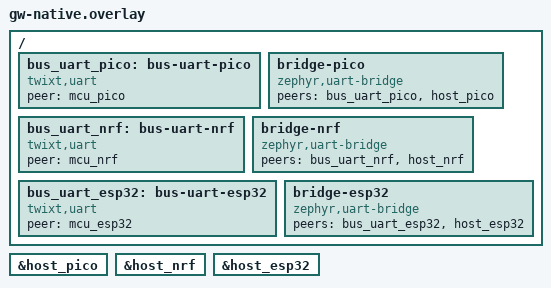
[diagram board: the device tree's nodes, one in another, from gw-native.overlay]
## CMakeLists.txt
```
# SPDX-License-Identifier: Apache-2.0
cmake_minimum_required(VERSION 3.20.0)

# CONF_FILE selects the hardware role; MCU selects a simulated bus participant.
set(role bd)
if(CONF_FILE MATCHES "gw.conf" OR MCU STREQUAL "gw")
  set(role gw)
endif()
set(CONF_FILE ${role}.conf)
list(PREPEND EXTRA_CONF_FILE ${CMAKE_CURRENT_SOURCE_DIR}/prj.conf)
set(role_overlay ${role}.overlay)

# Include the same board settings with either role, also under sysbuild.
set(board_target "${BOARD}")
if(BOARD_QUALIFIERS AND NOT BOARD MATCHES "/")
  string(APPEND board_target "/${BOARD_QUALIFIERS}")
endif()
string(REPLACE "/" "_" board_config "${board_target}")
if(EXISTS "${CMAKE_CURRENT_SOURCE_DIR}/boards/${board_config}.conf")
  list(APPEND EXTRA_CONF_FILE ${CMAKE_CURRENT_SOURCE_DIR}/boards/${board_config}.conf)
endif()

if(BOARD MATCHES "^native_sim")
  set(MCU pico CACHE STRING "Simulated MCU: pico, nrf, esp32 or gw")
  list(APPEND DTS_EXTRA_CPPFLAGS -DTWIXT_SELF_LABEL=mcu_${MCU} -DTWIXT_GATEWAY_LABEL=mcu_gw)
  if(role STREQUAL "gw")
    set(role_overlay gw-native.overlay)
  endif()
elseif(BOARD MATCHES "^nrf7002dk" AND role STREQUAL "gw")
  list(APPEND EXTRA_CONF_FILE ${CMAKE_CURRENT_SOURCE_DIR}/ble.conf)
  set(role_overlay gw-ble.overlay)
elseif(BOARD MATCHES "^rpi_pico" AND role STREQUAL "bd")
  list(APPEND DTS_EXTRA_CPPFLAGS -DTWIXT_GATEWAY_LABEL=mcu_nrf)
endif()
list(APPEND EXTRA_DTC_OVERLAY_FILE ${CMAKE_CURRENT_SOURCE_DIR}/${role_overlay})

find_package(Zephyr REQUIRED HINTS $ENV{ZEPHYR_BASE})
project(twixt_system)

target_sources(app PRIVATE src/main.c src/mcu_settings.c src/twixt_add.c)
target_sources_ifdef(CONFIG_TWIXT_USB_GATEWAY app PRIVATE src/usb.c)
target_sources_ifdef(CONFIG_BT app PRIVATE src/smp_proxy.c)
target_sources_ifdef(CONFIG_TWIXT_RP2040_WATCHDOG app PRIVATE src/watchdog.c)
```

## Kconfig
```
# SPDX-License-Identifier: Apache-2.0
mainmenu "Twixt system"

config TWIXT_GATEWAY
    bool "Gateway role"
    help
      Select the gateway role instead of a node with persistent storage.

source "Kconfig.zephyr"

config TWIXT_USB_GATEWAY
    def_bool TWIXT_GATEWAY && USB_DEVICE_STACK_NEXT

config TWIXT_RP2040_WATCHDOG
    def_bool TWIXT_GATEWAY && SOC_RP2040
    select WATCHDOG
```

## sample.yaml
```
# Copyright (c) 2026 Christoph Jans <jans.christoph@gmail.com>
# SPDX-License-Identifier: Apache-2.0

sample:
  name: twixt system
common:
  tags:
    - i2c
    - shell
tests:
  # The gateway, started by twister; pytest/test_system.py starts the
  # boards pico, nrf and esp32 next to it, from the builds below, on the same virtual bus
  app.twixt.system:
    platform_allow: native_sim
    integration_platforms:
      - native_sim
    extra_args: MCU=gw
    harness: pytest
    required_applications:
      - name: app.twixt.system.mcu_pico
      - name: app.twixt.system.mcu_nrf
      - name: app.twixt.system.mcu_esp32
  app.twixt.system.mcu_pico:
    platform_allow: native_sim
    extra_args: MCU=pico
    build_only: true
  app.twixt.system.mcu_nrf:
    platform_allow: native_sim
    extra_args: MCU=nrf
    build_only: true
  app.twixt.system.mcu_esp32:
    platform_allow: native_sim
    extra_args: MCU=esp32
    build_only: true
  app.twixt.system.pico_node:
    platform_allow: rpi_pico/rp2040/mcuboot
    extra_args: CONF_FILE=bd.conf
    build_only: true
  app.twixt.system.pico_gateway:
    platform_allow: rpi_pico/rp2040/mcuboot
    extra_args: CONF_FILE=gw.conf
    build_only: true
  app.twixt.system.nrf_node:
    platform_allow: nrf7002dk/nrf5340/cpuapp
    extra_args: CONF_FILE=bd.conf
    build_only: true
  app.twixt.system.nrf_ble_gateway:
    platform_allow: nrf7002dk/nrf5340/cpuapp
    sysbuild: true
    extra_args: twixt-system_CONF_FILE=gw.conf
    build_only: true
  app.twixt.system.esp_node:
    platform_allow: esp32_devkitc/esp32/procpu
    extra_args: CONF_FILE=bd.conf
    build_only: true
```

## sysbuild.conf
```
# Copyright (c) 2026 Christoph Jans
# SPDX-License-Identifier: Apache-2.0

SB_CONFIG_BOOTLOADER_MCUBOOT=y
```

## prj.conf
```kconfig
# SPDX-License-Identifier: Apache-2.0

# Shared bus, shell, settings and MCUmgr configuration.
CONFIG_I2C=y
CONFIG_SERIAL=y
CONFIG_LOG=y
CONFIG_LOG_BACKEND_SHOW_COLOR=n
CONFIG_SHELL=y
CONFIG_SHELL_LOG_BACKEND=n
CONFIG_SHELL_VT100_COLORS=n
CONFIG_SHELL_STACK_SIZE=4096
CONFIG_FLASH=y
CONFIG_FLASH_MAP=y
CONFIG_SETTINGS=y
CONFIG_TWIXT_SETTINGS=y
CONFIG_TWIXT_STRESS=y
CONFIG_SYSTEM_WORKQUEUE_STACK_SIZE=2048
CONFIG_TWIXT_SETTINGS_VALUE_MAX=32
CONFIG_MCUMGR=y
CONFIG_NET_BUF=y
CONFIG_ZCBOR=y
CONFIG_CRC=y
CONFIG_BASE64=y
CONFIG_MCUMGR_TRANSPORT_SHELL=y
CONFIG_STREAM_FLASH=y
CONFIG_IMG_MANAGER=y
CONFIG_IMG_ERASE_PROGRESSIVELY=y
CONFIG_MCUMGR_GRP_IMG=y
# OS management on shell, bus SMP, and BLE: echo, reset, and client parameters.
CONFIG_MCUMGR_GRP_OS=y
CONFIG_MCUMGR_GRP_OS_ECHO=y
CONFIG_MCUMGR_GRP_OS_MCUMGR_PARAMS=y
CONFIG_TWIXT_SMP=y
CONFIG_REBOOT=y
CONFIG_DEVICE_SHELL=y
CONFIG_GPIO=y
CONFIG_GPIO_SHELL=y
CONFIG_I2C_SHELL=y
CONFIG_TWIXT_LINK_NACK_RETRY_MS=20
```

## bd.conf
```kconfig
# SPDX-License-Identifier: Apache-2.0

CONFIG_TWIXT_GATEWAY=n
CONFIG_NVS=y
CONFIG_SETTINGS_NVS=y
CONFIG_SETTINGS_SHELL=y
CONFIG_FILE_SYSTEM=y
CONFIG_FILE_SYSTEM_LITTLEFS=y
CONFIG_FILE_SYSTEM_SHELL=y
CONFIG_MCUMGR_GRP_FS=y
CONFIG_MAIN_STACK_SIZE=2048
```

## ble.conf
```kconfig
# Copyright (c) 2026 Christoph Jans
# SPDX-License-Identifier: Apache-2.0

# Updates over Bluetooth for every MCU on the bus (twixt-system src/smp_proxy.c): an identity, an
# advertising set and a connection per MCU; the controller runs on the network core (hci_ipc,
# twixt-system sysbuild.cmake)
CONFIG_BT=y
CONFIG_BT_PERIPHERAL=y
CONFIG_BT_EXT_ADV=y
CONFIG_BT_EXT_ADV_MAX_ADV_SET=3
CONFIG_BT_ID_MAX=3
CONFIG_BT_MAX_CONN=3

# Large Bluetooth packets
CONFIG_BT_L2CAP_TX_MTU=498
CONFIG_BT_BUF_ACL_RX_SIZE=502
CONFIG_BT_BUF_ACL_TX_SIZE=502

# MCUmgr packets as large as the client may write
CONFIG_MCUMGR_TRANSPORT_NETBUF_SIZE=2475
CONFIG_MCUMGR_TRANSPORT_NETBUF_COUNT=6
CONFIG_MCUMGR_TRANSPORT_WORKQUEUE_STACK_SIZE=4608
```

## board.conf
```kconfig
# Copyright (c) 2026 Christoph Jans <jans.christoph@gmail.com>
# SPDX-License-Identifier: Apache-2.0

# Shell on the bus UART; the log stays on stdout, off the bus
CONFIG_SHELL=y
CONFIG_SHELL_LOG_BACKEND=n
CONFIG_SHELL_VT100_COLORS=n
# fs_dirent and the littlefs calls of the "fs" commands
CONFIG_SHELL_STACK_SIZE=4096

# The setting mcu/name, for the others; "twixt get/set" in the shell. Settings
# are kept in NVS on the settings partition.
CONFIG_FLASH=y
CONFIG_FLASH_MAP=y
CONFIG_NVS=y
CONFIG_SETTINGS=y
CONFIG_SETTINGS_NVS=y
CONFIG_TWIXT_SETTINGS=y
CONFIG_SYSTEM_WORKQUEUE_STACK_SIZE=2048

# littlefs on the storage partition, mounted at /lfs (fstab in board.overlay);
# "fs" in the shell
CONFIG_FILE_SYSTEM=y
CONFIG_FILE_SYSTEM_LITTLEFS=y
CONFIG_FILE_SYSTEM_SHELL=y

# MCUmgr (SMP) on the shell, for the laptop: files on /lfs (fs group) and
# firmware images into slot 1 (img group)
CONFIG_MCUMGR=y
CONFIG_NET_BUF=y
CONFIG_ZCBOR=y
CONFIG_CRC=y
CONFIG_BASE64=y
CONFIG_MCUMGR_TRANSPORT_SHELL=y
CONFIG_MCUMGR_GRP_FS=y
CONFIG_STREAM_FLASH=y
CONFIG_IMG_MANAGER=y
CONFIG_MCUMGR_GRP_IMG=y
```

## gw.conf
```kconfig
# SPDX-License-Identifier: Apache-2.0

CONFIG_TWIXT_GATEWAY=y
CONFIG_SETTINGS_NONE=y
```

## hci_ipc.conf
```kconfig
# Copyright (c) 2026 Christoph Jans
# SPDX-License-Identifier: Apache-2.0

# The controller for the twixt-ble snippet (src/smp_proxy.c): an advertising set per MCU, large
# packets
CONFIG_BT_EXT_ADV=y
CONFIG_BT_CTLR_ADV_SET=3
CONFIG_BT_CTLR_DATA_LENGTH_MAX=251
CONFIG_BT_BUF_ACL_RX_SIZE=251
CONFIG_BT_BUF_ACL_TX_SIZE=251
```

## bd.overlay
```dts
/*
 * Copyright (c) 2026 Christoph Jans
 * SPDX-License-Identifier: Apache-2.0
 */

/* A board: its shell is on a UART over the bus to the gateway. Settings are in
 * NVS on settings_partition, littlefs on storage_partition is mounted at /lfs.
 * Included by each board overlay (boards/), which adds the bus, the partitions
 * and which MCU the board is (twixt,self).
 */

#ifndef TWIXT_GATEWAY_LABEL
#define TWIXT_GATEWAY_LABEL mcu_pico
#endif

/ {
	chosen {
		zephyr,shell-uart = &bus_uart;
		zephyr,settings-partition = &settings_partition;
	};

	bus_uart: bus-uart {
		compatible = "twixt,uart";
		peer = <&TWIXT_GATEWAY_LABEL>;
	};

	fstab {
		compatible = "zephyr,fstab";

		lfs: lfs {
			compatible = "zephyr,fstab,littlefs";
			mount-point = "/lfs";
			partition = <&storage_partition>;
			automount;
			read-size = <16>;
			prog-size = <16>;
			cache-size = <64>;
			lookahead-size = <32>;
			block-cycles = <512>;
		};
	};
};
```

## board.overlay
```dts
/*
 * Copyright (c) 2026 Christoph Jans <jans.christoph@gmail.com>
 *
 * SPDX-License-Identifier: Apache-2.0
 */

/* A board: its shell is on a UART over the bus, to the gateway. Settings are in
 * NVS on settings_partition, and littlefs on storage_partition is mounted at
 * /lfs, for the "fs" shell commands; where the partitions are is up to the
 * board (boards/<board>.overlay).
 */

/ {
	chosen {
		zephyr,shell-uart = &bus_uart;
		zephyr,settings-partition = &settings_partition;
	};

	bus_uart: bus-uart {
		compatible = "twixt,uart";
		peer = <&mcu_gw>;
	};

	fstab {
		compatible = "zephyr,fstab";

		lfs: lfs {
			compatible = "zephyr,fstab,littlefs";
			mount-point = "/lfs";
			partition = <&storage_partition>;
			automount;
			read-size = <16>;
			prog-size = <16>;
			cache-size = <64>;
			lookahead-size = <32>;
			block-cycles = <512>;
		};
	};
};
```

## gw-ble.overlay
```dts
/* SPDX-License-Identifier: Apache-2.0 */

/* BLE management gateway; keep its shell reachable through the Pico USB port. */
/ {
	chosen {
		zephyr,shell-uart = &bus_uart;
	};

	bus_uart: bus-uart {
		compatible = "twixt,uart";
		peer = <&mcu_pico>;
	};
};
```

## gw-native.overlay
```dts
/*
 * Copyright (c) 2026 Christoph Jans <jans.christoph@gmail.com>
 *
 * SPDX-License-Identifier: Apache-2.0
 */

/* The console gateway: per board a UART over the bus, bridged to a serial port
 * to the laptop, host_<board>. The board's overlay (boards/) has the host ports,
 * disabled: a PTY on native_sim, USB CDC-ACM on the Raspberry Pi Pico.
 */

/ {
	bus_uart_pico: bus-uart-pico {
		compatible = "twixt,uart";
		peer = <&mcu_pico>;
	};

	bridge-pico {
		compatible = "zephyr,uart-bridge";
		peers = <&bus_uart_pico &host_pico>;
	};

	bus_uart_nrf: bus-uart-nrf {
		compatible = "twixt,uart";
		peer = <&mcu_nrf>;
	};

	bridge-nrf {
		compatible = "zephyr,uart-bridge";
		peers = <&bus_uart_nrf &host_nrf>;
	};

	bus_uart_esp32: bus-uart-esp32 {
		compatible = "twixt,uart";
		peer = <&mcu_esp32>;
	};

	bridge-esp32 {
		compatible = "zephyr,uart-bridge";
		peers = <&bus_uart_esp32 &host_esp32>;
	};
};

&host_pico {
	status = "okay";
};

&host_nrf {
	status = "okay";
};

&host_esp32 {
	status = "okay";
};
```

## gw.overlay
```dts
/*
 * Copyright (c) 2026 Christoph Jans
 * SPDX-License-Identifier: Apache-2.0
 */

/* USB gateway bridges remote shells to host ports. */

/ {
	chosen {
		zephyr,shell-uart = &host_gw;
	};


	bus_uart_nrf: bus-uart-nrf {
		compatible = "twixt,uart";
		peer = <&mcu_nrf>;
	};

	bridge-nrf {
		compatible = "zephyr,uart-bridge";
		peers = <&bus_uart_nrf &host_nrf>;
	};

	bus_uart_esp32: bus-uart-esp32 {
		compatible = "twixt,uart";
		peer = <&mcu_esp32>;
	};

	bridge-esp32 {
		compatible = "zephyr,uart-bridge";
		peers = <&bus_uart_esp32 &host_esp32>;
	};
};
```

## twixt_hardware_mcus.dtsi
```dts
/*
 * Copyright (c) 2026 Christoph Jans
 * SPDX-License-Identifier: Apache-2.0
 */

/* The MCUs on the bus, included in the bus node of each board overlay; shared by nodes and gateways.
 */


mcu_nrf: nrf@11 {
	compatible = "twixt,mcu";
	reg = <0x11>;
};

mcu_pico: pico@70 {
	compatible = "twixt,mcu";
	reg = <0x70>;
};

mcu_esp32: esp32@12 {
	compatible = "twixt,mcu";
	reg = <0x12>;
};
```

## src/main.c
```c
/* SPDX-License-Identifier: Apache-2.0 */

#include <stdio.h>
#include <zephyr/app_version.h>
#include <zephyr/kernel.h>
#include <zephyr/logging/log.h>
#include <zephyr/settings/settings.h>
#include <zephyr/shell/shell_uart.h>
#include <twixt/twixt.h>

LOG_MODULE_REGISTER(twixt_system, LOG_LEVEL_INF);

#ifdef CONFIG_TWIXT_USB_GATEWAY
int twixt_usb_init(void);
#endif

int main(void)
{
	static char prompt[32];
	int ret = settings_subsys_init();

	if (ret == 0) {
		ret = settings_load();
	}
	if (ret) {
		LOG_ERR("settings: %d", ret);
	}
#ifdef CONFIG_TWIXT_USB_GATEWAY
	ret = twixt_usb_init();
	if (ret) {
		LOG_ERR("USB: %d", ret);
	}
#endif
	if (IS_ENABLED(CONFIG_SHELL)) {
		snprintf(prompt, sizeof(prompt), "%s:~$ ", twixt_self_name());
		shell_prompt_change(shell_backend_uart_get_ptr(), prompt);
	}
	LOG_INF("%s at 0x%02x: %s, v%s", twixt_self_name(), twixt_self_addr(),
		IS_ENABLED(CONFIG_TWIXT_GATEWAY) ? "gateway" : "node", APP_VERSION_STRING);
	return 0;
}
```

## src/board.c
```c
/*
 * Copyright (c) 2026 Christoph Jans <jans.christoph@gmail.com>
 *
 * SPDX-License-Identifier: Apache-2.0
 *
 * A board on the bus: its shell is on a UART over the bus to the gateway
 * (board.overlay), and it serves one read-only setting, mcu/name, that the
 * others can get ("twixt get <addr> mcu/name"). Its settings are in NVS on the
 * settings partition; littlefs on the storage partition is mounted at /lfs.
 */

#include <stdio.h>
#include <string.h>
#include <zephyr/kernel.h>
#include <zephyr/logging/log.h>
#include <zephyr/settings/settings.h>
#include <zephyr/shell/shell_uart.h>

#include <twixt/twixt.h>

LOG_MODULE_REGISTER(board, LOG_LEVEL_INF);

/* Runs in the I2C target interrupt too: a constant needs no lock */
static int mcu_get(const char *key, char *val, int val_len_max)
{
	int len = strlen(twixt_self_name());

	if (!settings_name_steq(key, "name", NULL)) {
		return -ENOENT;
	}
	if (len > val_len_max) {
		return -ENOMEM;
	}
	memcpy(val, twixt_self_name(), len);
	return len;
}

static int mcu_set(const char *key, size_t len, settings_read_cb read_cb, void *cb_arg)
{
	return settings_name_steq(key, "name", NULL) ? -EACCES : -ENOENT;
}

SETTINGS_STATIC_HANDLER_DEFINE(mcu, "mcu", mcu_get, mcu_set, NULL, NULL);

int main(void)
{
	static char prompt[32];
	int ret;

	ret = settings_subsys_init();
	if (ret) {
		LOG_ERR("settings: %d", ret);
	}

	snprintf(prompt, sizeof(prompt), "%s:~$ ", twixt_self_name());
	shell_prompt_change(shell_backend_uart_get_ptr(), prompt);

	LOG_INF("%s at 0x%02x, shell on the bus", twixt_self_name(), twixt_self_addr());
	return 0;
}
```

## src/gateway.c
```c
/*
 * Copyright (c) 2026 Christoph Jans <jans.christoph@gmail.com>
 *
 * SPDX-License-Identifier: Apache-2.0
 *
 * The console gateway: devicetree does the work (gateway.overlay). With USB
 * CDC-ACM ports to the laptop (Raspberry Pi Pico), it brings up the USB device
 * with all of them.
 */

#include <zephyr/kernel.h>
#include <zephyr/logging/log.h>

#include <twixt/twixt.h>

LOG_MODULE_REGISTER(gateway, LOG_LEVEL_INF);

#if DT_HAS_COMPAT_STATUS_OKAY(zephyr_cdc_acm_uart)

#include <zephyr/usb/usbd.h>

/* Zephyr's VID and a PID for testing; a product needs its own */
USBD_DEVICE_DEFINE(gw_usbd, DEVICE_DT_GET(DT_NODELABEL(zephyr_udc0)), 0x2fe3, 0x0004);
USBD_DESC_LANG_DEFINE(gw_lang);
USBD_DESC_MANUFACTURER_DEFINE(gw_mfr, "twixt");
USBD_DESC_PRODUCT_DEFINE(gw_product, "twixt console gateway");
USBD_DESC_CONFIG_DEFINE(gw_cfg_desc, "FS Configuration");
USBD_CONFIGURATION_DEFINE(gw_config, 0, 125, &gw_cfg_desc);

static int usb_init(void)
{
	struct usbd_desc_node *const descs[] = {&gw_lang, &gw_mfr, &gw_product};
	int err;

	for (size_t i = 0; i < ARRAY_SIZE(descs); i++) {
		err = usbd_add_descriptor(&gw_usbd, descs[i]);
		if (err) {
			return err;
		}
	}
	err = usbd_add_configuration(&gw_usbd, USBD_SPEED_FS, &gw_config);
	if (err) {
		return err;
	}
	/* All CDC-ACM ports of the devicetree */
	err = usbd_register_all_classes(&gw_usbd, USBD_SPEED_FS, 1, NULL);
	if (err) {
		return err;
	}
	/* CDC-ACM has more than one interface per port: interface association */
	usbd_device_set_code_triple(&gw_usbd, USBD_SPEED_FS, USB_BCC_MISCELLANEOUS, 0x02, 0x01);

	err = usbd_init(&gw_usbd);
	if (err) {
		return err;
	}
	return usbd_enable(&gw_usbd);
}

#endif

int main(void)
{
#if DT_HAS_COMPAT_STATUS_OKAY(zephyr_cdc_acm_uart)
	int err = usb_init();

	if (err) {
		LOG_ERR("USB: %d", err);
	}
#endif
	LOG_INF("%s at 0x%02x: console gateway", twixt_name(), twixt_addr());
	return 0;
}
```

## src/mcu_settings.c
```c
/*
 * Copyright (c) 2026 Christoph Jans
 * SPDX-License-Identifier: Apache-2.0
 */

/*
 * The settings of this MCU, for "twixt get/set" on the others: mcu/name (read
 * only), mcu/label (saved where the MCU has a settings backend) and mcu/dump
 * (RAM only). They are served in the I2C target interrupt too. Shared by nodes and gateways.
 */

#include <string.h>
#include <zephyr/kernel.h>
#include <zephyr/settings/settings.h>

#include <twixt/twixt.h>

struct value {
	uint8_t data[CONFIG_TWIXT_SETTINGS_VALUE_MAX];
	size_t len;
};

static struct k_spinlock lock;
static struct value label;
static struct value dump;

static struct value *find(const char *key)
{
	if (settings_name_steq(key, "label", NULL)) {
		return &label;
	}
	if (settings_name_steq(key, "dump", NULL)) {
		return &dump;
	}
	return NULL;
}

static int mcu_get(const char *key, char *val, int val_len_max)
{
	struct value *v = find(key);
	int ret = -ENOMEM;

	if (settings_name_steq(key, "name", NULL)) {
		ret = strlen(twixt_self_name());
		if (ret > val_len_max) {
			return -ENOMEM;
		}
		memcpy(val, twixt_self_name(), ret);
		return ret;
	}
	if (v == NULL) {
		return -ENOENT;
	}
	K_SPINLOCK(&lock) {
		if (v->len <= val_len_max) {
			memcpy(val, v->data, v->len);
			ret = v->len;
		}
	}
	return ret;
}

static int mcu_set(const char *key, size_t len, settings_read_cb read_cb, void *cb_arg)
{
	struct value *v = find(key);
	uint8_t buf[CONFIG_TWIXT_SETTINGS_VALUE_MAX];
	ssize_t n;

	if (settings_name_steq(key, "name", NULL)) {
		return -EACCES;
	}
	if (v == NULL) {
		return -ENOENT;
	}
	if (len > sizeof(buf)) {
		return -ENOMEM;
	}
	n = read_cb(cb_arg, buf, len);
	if (n < 0) {
		return n;
	}
	K_SPINLOCK(&lock) {
		memcpy(v->data, buf, n);
		v->len = n;
	}
	return 0;
}

static int mcu_export(int (*cb)(const char *name, const void *value, size_t val_len))
{
	struct value copy;

	K_SPINLOCK(&lock) {
		copy = label;
	}
	return cb("mcu/label", copy.data, copy.len);
}

SETTINGS_STATIC_HANDLER_DEFINE(mcu, "mcu", mcu_get, mcu_set, NULL, mcu_export);
```

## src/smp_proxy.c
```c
/*
 * Copyright (c) 2026 Christoph Jans
 * SPDX-License-Identifier: Apache-2.0
 */

/* MCUmgr over BLE: one identity and advertising set for each MCU.
 * Local requests go to MCUmgr; remote requests and responses use twixt SMP.
 */

#include <string.h>
#include <zephyr/bluetooth/bluetooth.h>
#include <zephyr/bluetooth/conn.h>
#include <zephyr/bluetooth/gatt.h>
#include <zephyr/init.h>
#include <zephyr/kernel.h>
#include <zephyr/logging/log.h>
#include <zephyr/mgmt/mcumgr/mgmt/handlers.h>
#include <zephyr/mgmt/mcumgr/mgmt/mgmt_defines.h>
#include <zephyr/mgmt/mcumgr/smp/smp.h>
#include <zephyr/mgmt/mcumgr/transport/smp.h>
#include <zephyr/mgmt/mcumgr/transport/smp_bt.h>
#include <zephyr/sys/byteorder.h>

#include <mgmt/mcumgr/transport/smp_internal.h>

#include <twixt/service/smp.h>
#include <twixt/twixt.h>

LOG_MODULE_REGISTER(smp_proxy, LOG_LEVEL_INF);

#define SMP_HDR_LEN 8
#define NOTIFY_HDR  3

struct route {
	const char *name;
	uint8_t addr;
	struct bt_le_ext_adv *adv;
	struct bt_conn *conn;
	struct net_buf *rx; /* the packet the client is writing */
};

/* Index = Bluetooth identity; the first is this board */
static struct route routes[] = {
	{.name = "twixt-nrf", .addr = DT_REG_ADDR(DT_NODELABEL(mcu_nrf))},
	{.name = "twixt-pico", .addr = DT_REG_ADDR(DT_NODELABEL(mcu_pico))},
	{.name = "twixt-esp32", .addr = DT_REG_ADDR(DT_NODELABEL(mcu_esp32))},
};

BUILD_ASSERT(ARRAY_SIZE(routes) <= CONFIG_BT_ID_MAX, "an identity per route");

static struct smp_transport local_transport;
static K_FIFO_DEFINE(remote_fifo);

static ssize_t smp_write(struct bt_conn *conn, const struct bt_gatt_attr *attr, const void *buf,
			 uint16_t len, uint16_t offset, uint8_t flags);

BT_GATT_SERVICE_DEFINE(smp_proxy_svc,
	BT_GATT_PRIMARY_SERVICE(BT_UUID_DECLARE_128(SMP_BT_SVC_UUID_VAL)),
	BT_GATT_CHARACTERISTIC(BT_UUID_DECLARE_128(SMP_BT_CHR_UUID_VAL),
			       BT_GATT_CHRC_WRITE_WITHOUT_RESP | BT_GATT_CHRC_NOTIFY,
			       BT_GATT_PERM_WRITE, NULL, smp_write, NULL),
	BT_GATT_CCC(NULL, BT_GATT_PERM_READ | BT_GATT_PERM_WRITE),
);

static struct route *route_of(struct bt_conn *conn)
{
	struct bt_conn_info info;

	if (bt_conn_get_info(conn, &info) != 0 || info.id >= ARRAY_SIZE(routes)) {
		return NULL;
	}
	return &routes[info.id];
}

static int notify(struct route *r, const uint8_t *data, size_t len)
{
	struct bt_conn *conn = r->conn;
	size_t off = 0;

	if (conn == NULL) {
		return -ENOTCONN;
	}
	while (off < len) {
		uint16_t chunk = MIN(len - off, bt_gatt_get_mtu(conn) - NOTIFY_HDR);
		int err = bt_gatt_notify(conn, &smp_proxy_svc.attrs[2], &data[off], chunk);

		if (err == -ENOMEM) {
			k_msleep(1);
			continue;
		}
		if (err) {
			return err;
		}
		off += chunk;
	}
	return 0;
}

/* The packet is whole once its header and as many bytes as the header says are in */
static ssize_t smp_write(struct bt_conn *conn, const struct bt_gatt_attr *attr, const void *buf,
			 uint16_t len, uint16_t offset, uint8_t flags)
{
	struct route *r = route_of(conn);
	size_t want;

	if (r == NULL) {
		return BT_GATT_ERR(BT_ATT_ERR_UNLIKELY);
	}
	if (r->rx == NULL) {
		r->rx = smp_packet_alloc();
		if (r->rx == NULL) {
			return BT_GATT_ERR(BT_ATT_ERR_INSUFFICIENT_RESOURCES);
		}
	}
	if (net_buf_tailroom(r->rx) < len) {
		smp_packet_free(r->rx);
		r->rx = NULL;
		return BT_GATT_ERR(BT_ATT_ERR_INSUFFICIENT_RESOURCES);
	}
	net_buf_add_mem(r->rx, buf, len);
	if (r->rx->len < SMP_HDR_LEN) {
		return len;
	}
	want = SMP_HDR_LEN + sys_get_be16(&r->rx->data[2]);
	if (r->rx->len < want) {
		return len;
	}
	if (r->rx->len > want) {
		LOG_WRN("%s: %u bytes past the packet dropped", r->name, r->rx->len - want);
		r->rx->len = want;
	}

	if (r->addr == twixt_self_addr()) {
		smp_rx_req(&local_transport, r->rx);
	} else {
		*(uint8_t *)net_buf_user_data(r->rx) = r - routes;
		k_fifo_put(&remote_fifo, r->rx);
	}
	r->rx = NULL;
	return len;
}

static int local_output(struct net_buf *nb)
{
	int err = notify(&routes[0], nb->data, nb->len);

	smp_packet_free(nb);
	return err ? MGMT_ERR_EUNKNOWN : MGMT_ERR_EOK;
}

static void local_setup(void)
{
	local_transport.functions.output = local_output;
	if (smp_transport_init(&local_transport) != 0) {
		LOG_ERR("SMP transport init failed");
	}
}

MCUMGR_HANDLER_DEFINE(smp_proxy, local_setup);

/* Packets to the other MCUs go out here */
static void sender(void *p1, void *p2, void *p3)
{
	for (;;) {
		struct net_buf *nb = k_fifo_get(&remote_fifo, K_FOREVER);
		struct route *r = &routes[*(uint8_t *)net_buf_user_data(nb)];
		int err = twixt_smp_send(r->addr, nb->data, nb->len);

		if (err) {
			LOG_WRN("%s: %d", r->name, err);
		}
		smp_packet_free(nb);
	}
}

K_THREAD_DEFINE(smp_proxy_tx, 1024, sender, NULL, NULL, NULL, K_LOWEST_APPLICATION_THREAD_PRIO,
		0, 0);

/* Their answers come back here */
static void receiver(void *p1, void *p2, void *p3)
{
	for (;;) {
		uint8_t src;
		struct net_buf *nb = twixt_smp_rsp_get(&src, K_FOREVER);

		for (size_t i = 0; i < ARRAY_SIZE(routes); i++) {
			if (routes[i].addr == src) {
				(void)notify(&routes[i], nb->data, nb->len);
			}
		}
		smp_packet_free(nb);
	}
}

K_THREAD_DEFINE(smp_proxy_rx, 1024, receiver, NULL, NULL, NULL, K_LOWEST_APPLICATION_THREAD_PRIO,
		0, 0);

static void advertise(struct k_work *work)
{
	for (size_t i = 0; i < ARRAY_SIZE(routes); i++) {
		int err;

		if (routes[i].adv == NULL || routes[i].conn != NULL) {
			continue;
		}
		err = bt_le_ext_adv_start(routes[i].adv, BT_LE_EXT_ADV_START_DEFAULT);
		if (err && err != -EALREADY) {
			LOG_ERR("%s: advertising: %d", routes[i].name, err);
		}
	}
}

static K_WORK_DEFINE(advertise_work, advertise);

static void connected(struct bt_conn *conn, uint8_t err)
{
	struct route *r = err ? NULL : route_of(conn);

	if (r == NULL) {
		return;
	}
	if (r->conn != NULL) {
		(void)bt_conn_disconnect(conn, BT_HCI_ERR_REMOTE_USER_TERM_CONN);
		return;
	}
	r->conn = bt_conn_ref(conn);
	LOG_INF("%s: connected", r->name);
}

static void disconnected(struct bt_conn *conn, uint8_t reason)
{
	struct route *r = route_of(conn);

	if (r == NULL || r->conn != conn) {
		return;
	}
	bt_conn_unref(r->conn);
	r->conn = NULL;
	if (r->rx != NULL) {
		smp_packet_free(r->rx);
		r->rx = NULL;
	}
	LOG_INF("%s: disconnected, 0x%02x", r->name, reason);
}

static void recycled(void)
{
	k_work_submit(&advertise_work);
}

BT_CONN_CB_DEFINE(smp_proxy_conn_cb) = {
	.connected = connected,
	.disconnected = disconnected,
	.recycled = recycled,
};

/* Identity 0 is the controller's; the others differ from it in the lowest address byte */
static int create_identities(void)
{
	bt_addr_le_t addrs[CONFIG_BT_ID_MAX];
	size_t count = ARRAY_SIZE(addrs);

	bt_id_get(addrs, &count);
	for (size_t i = count; i < ARRAY_SIZE(routes); i++) {
		bt_addr_le_t addr = addrs[0];
		int id;

		addr.a.val[0] ^= i;
		id = bt_id_create(&addr, NULL);
		if (id != i) {
			return id < 0 ? id : -EINVAL;
		}
	}
	return 0;
}

static const struct bt_data ad[] = {
	BT_DATA_BYTES(BT_DATA_FLAGS, (BT_LE_AD_GENERAL | BT_LE_AD_NO_BREDR)),
	BT_DATA_BYTES(BT_DATA_UUID128_ALL, SMP_BT_SVC_UUID_VAL),
};

static int smp_proxy_init(void)
{
	int err = bt_enable(NULL);

	if (err == 0) {
		err = create_identities();
	}
	for (size_t i = 0; err == 0 && i < ARRAY_SIZE(routes); i++) {
		struct bt_le_adv_param param = BT_LE_ADV_PARAM_INIT(
			BT_LE_ADV_OPT_CONN, BT_GAP_ADV_FAST_INT_MIN_2, BT_GAP_ADV_FAST_INT_MAX_2, NULL);
		const struct bt_data sd[] = {
			BT_DATA(BT_DATA_NAME_COMPLETE, routes[i].name, strlen(routes[i].name)),
		};

		param.id = i;
		err = bt_le_ext_adv_create(&param, NULL, &routes[i].adv);
		if (err == 0) {
			err = bt_le_ext_adv_set_data(routes[i].adv, ad, ARRAY_SIZE(ad), sd,
						     ARRAY_SIZE(sd));
		}
	}
	if (err) {
		LOG_ERR("Bluetooth: %d", err);
		return 0;
	}
	k_work_submit(&advertise_work);
	return 0;
}

SYS_INIT(smp_proxy_init, APPLICATION, CONFIG_APPLICATION_INIT_PRIORITY);
```

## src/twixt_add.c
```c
/* SPDX-License-Identifier: Apache-2.0 */

#include <zephyr/shell/shell.h>
#include <zephyr/sys/byteorder.h>

#include <twixt/twixt.h>

#define ADD_SERVICE TWIXT_SERVICE_APP

static int add(const struct twixt_req *req, uint8_t *rsp_data)
{
	if (req->len != 8) {
		return -EINVAL;
	}
	sys_put_le32(sys_get_le32(&req->data[0]) + sys_get_le32(&req->data[4]), rsp_data);
	return 4;
}

TWIXT_SERVICE_DEFINE(add_service, ADD_SERVICE, add);

#ifdef CONFIG_TWIXT_SHELL
static int cmd_add(const struct shell *sh, size_t argc, char **argv)
{
	int err = 0;
	unsigned long addr = shell_strtoul(argv[1], 0, &err);

	if (err || addr > 0x7f) {
		shell_error(sh, "invalid address: %s", argv[1]);
		return -EINVAL;
	}
	long a = shell_strtol(argv[2], 0, &err);

	if (err) {
		shell_error(sh, "invalid number: %s", argv[2]);
		return -EINVAL;
	}
	long b = shell_strtol(argv[3], 0, &err);

	if (err) {
		shell_error(sh, "invalid number: %s", argv[3]);
		return -EINVAL;
	}

	uint8_t req[8];
	uint8_t rsp[4];

	sys_put_le32(a, &req[0]);
	sys_put_le32(b, &req[4]);
	int ret = twixt_request(addr, ADD_SERVICE, req, sizeof(req), rsp, sizeof(rsp));

	if (ret) {
		shell_error(sh, "0x%02lx: %d", addr, ret);
		return ret;
	}
	shell_print(sh, "%d", (int32_t)sys_get_le32(rsp));
	return 0;
}
SHELL_SUBCMD_ADD((twixt), add, NULL, "<addr> <a> <b>: add two numbers on the MCU at <addr>",
		 cmd_add, 4, 0);
#endif /* CONFIG_TWIXT_SHELL */
```

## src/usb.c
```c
/* SPDX-License-Identifier: Apache-2.0 */

#include <zephyr/kernel.h>

#include <zephyr/usb/usbd.h>

/* Zephyr's VID and a PID for testing; a product needs its own */
USBD_DEVICE_DEFINE(gw_usbd, DEVICE_DT_GET(DT_NODELABEL(zephyr_udc0)), 0x2fe3, 0x0004);
USBD_DESC_LANG_DEFINE(gw_lang);
USBD_DESC_MANUFACTURER_DEFINE(gw_mfr, "twixt");
USBD_DESC_PRODUCT_DEFINE(gw_product, "twixt pico");
USBD_DESC_CONFIG_DEFINE(gw_cfg_desc, "FS Configuration");
USBD_CONFIGURATION_DEFINE(gw_config, 0, 125, &gw_cfg_desc);

/* Resolve each CDC class by its devicetree port, then register in host order.
 * Each CDC port occupies two USB interfaces: if00, if02, if04.
 */
#define DT_DRV_COMPAT zephyr_cdc_acm_uart
#define CDC_CLASS_FOR_INSTANCE(n)                                                                  \
	if (dev == DEVICE_DT_GET(DT_INST(n, zephyr_cdc_acm_uart))) {                               \
		return "cdc_acm_" STRINGIFY(n);                                                    \
	}

static const char *cdc_class(const struct device *dev)
{
	DT_INST_FOREACH_STATUS_OKAY(CDC_CLASS_FOR_INSTANCE)
	return NULL;
}

int twixt_usb_init(void)
{
	struct usbd_desc_node *const descs[] = {&gw_lang, &gw_mfr, &gw_product};
	int err;

	for (size_t i = 0; i < ARRAY_SIZE(descs); i++) {
		err = usbd_add_descriptor(&gw_usbd, descs[i]);
		if (err) {
			return err;
		}
	}
	err = usbd_add_configuration(&gw_usbd, USBD_SPEED_FS, &gw_config);
	if (err) {
		return err;
	}
	const struct device *const ports[] = {
		DEVICE_DT_GET(DT_NODELABEL(host_gw)),
		DEVICE_DT_GET(DT_NODELABEL(host_nrf)),
		DEVICE_DT_GET(DT_NODELABEL(host_esp32)),
	};

	for (size_t i = 0; i < ARRAY_SIZE(ports); i++) {
		err = usbd_register_class(&gw_usbd, cdc_class(ports[i]), USBD_SPEED_FS, 1);
		if (err) {
			return err;
		}
	}
	usbd_device_set_code_triple(&gw_usbd, USBD_SPEED_FS, USB_BCC_MISCELLANEOUS, 0x02, 0x01);
	err = usbd_init(&gw_usbd);
	return err ? err : usbd_enable(&gw_usbd);
}
```

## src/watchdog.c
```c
/*
 * Copyright (c) 2026 Christoph Jans
 * SPDX-License-Identifier: Apache-2.0
 */

/*
 * The hardware watchdog reboots a hung gateway, which then logs it and keeps it for "gw_reset".
 * Watchdog scratch registers 0 and 1 survive the reset (the driver and the bootrom use 4-7).
 */

#include <zephyr/drivers/watchdog.h>
#include <zephyr/kernel.h>
#include <zephyr/logging/log.h>
#include <zephyr/shell/shell.h>

#include <hardware/structs/watchdog.h>

LOG_MODULE_REGISTER(gw_watchdog, LOG_LEVEL_INF);

#define TIMEOUT_MS  2000
#define FEED_MS     500
#define SOFT_REBOOT 0x7b1cffffU
#define MARK        0 /* SOFT_REBOOT before a reboot by software */
#define FED_MS      1 /* uptime of the last feed */

static const struct device *const wdt = DEVICE_DT_GET(DT_ALIAS(watchdog0));
static bool by_watchdog;
static uint32_t fed_ms;

/* A reboot by software leaves WATCHDOG REASON as it was: mark it, so that it does not count */
void sys_arch_reboot(int type)
{
	ARG_UNUSED(type);
	(void)irq_lock();
	watchdog_hw->scratch[MARK] = SOFT_REBOOT;
	NVIC_SystemReset();
}

static int read_reset(void)
{
	by_watchdog = (watchdog_hw->reason & WATCHDOG_REASON_TIMER_BITS) != 0U &&
		      watchdog_hw->scratch[MARK] != SOFT_REBOOT;
	fed_ms = watchdog_hw->scratch[FED_MS];
	watchdog_hw->scratch[MARK] = 0;
	return 0;
}

SYS_INIT(read_reset, PRE_KERNEL_1, 0);

static void feed(void *p1, void *p2, void *p3)
{
	const struct wdt_timeout_cfg cfg = {
		.window.max = TIMEOUT_MS,
		.flags = WDT_FLAG_RESET_SOC,
	};
	int channel = wdt_install_timeout(wdt, &cfg);
	int ret = channel < 0 ? channel : wdt_setup(wdt, WDT_OPT_PAUSE_HALTED_BY_DBG);

	if (by_watchdog) {
		LOG_ERR("WATCHDOG RESET: hung after %u ms", fed_ms);
	}
	if (ret != 0) {
		LOG_ERR("watchdog: %d", ret);
		return;
	}
	for (;;) {
		(void)wdt_feed(wdt, channel);
		watchdog_hw->scratch[FED_MS] = k_uptime_get_32();
		k_msleep(FEED_MS);
	}
}

K_THREAD_DEFINE(gw_wdt_feed, 512, feed, NULL, NULL, NULL, K_LOWEST_APPLICATION_THREAD_PRIO - 1,
		0, 0);

static int cmd_reset(const struct shell *sh, size_t argc, char **argv)
{
	if (by_watchdog) {
		shell_print(sh, "last reset: WATCHDOG, hung after %u ms", fed_ms);
	} else {
		shell_print(sh, "last reset: not by the watchdog");
	}
	return 0;
}

SHELL_CMD_REGISTER(gw_reset, NULL, "whether the watchdog rebooted the gateway", cmd_reset);
```
